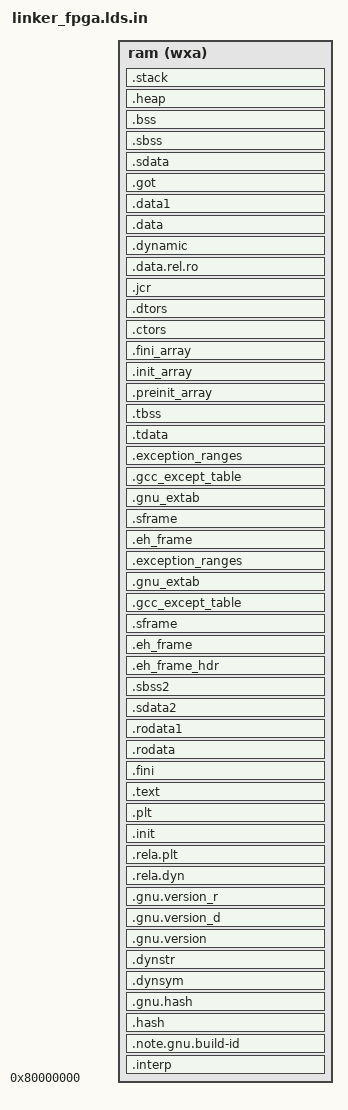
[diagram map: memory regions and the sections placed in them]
/* Patched script for RISC-V CPU */
/* Obtained using riscv32-unknown-elf-ld --verbose */

/* Copyright (C) 2014-2023 Free Software Foundation, Inc.
   Copying and distribution of this script, with or without modification,
   are permitted in any medium without royalty provided the copyright
   notice and this notice are preserved.  */

/*
Needs symbols from rvtarget.h
Memory sizes and origins
Heap and stack sizes
*/
#include <rvtarget.h>

OUTPUT_FORMAT("elf32-littleriscv", "elf32-littleriscv", "elf32-littleriscv")
OUTPUT_ARCH(riscv)
ENTRY(__rv_init) /* Setup boot as entry point */

/* Memory config of RISC-V CPU */
MEMORY
{
  ram (wxa)     : ORIGIN = 0x80000000,    LENGTH = FPGA_RAM_SIZE
}

SECTIONS
{
  /* Read-only sections, merged into text segment: */
  PROVIDE (__executable_start = SEGMENT_START("text-segment", 0x00000)); . = SEGMENT_START("text-segment", 0x00000);
  .interp         : { *(.interp) } > ram
  .note.gnu.build-id  : { *(.note.gnu.build-id) } > ram
  .hash           : { *(.hash) } > ram
  .gnu.hash       : { *(.gnu.hash) } > ram
  .dynsym         : { *(.dynsym) } > ram
  .dynstr         : { *(.dynstr) } > ram
  .gnu.version    : { *(.gnu.version) } > ram
  .gnu.version_d  : { *(.gnu.version_d) } > ram
  .gnu.version_r  : { *(.gnu.version_r) } > ram
  .rela.dyn       :
    {
      *(.rela.init)
      *(.rela.text .rela.text.* .rela.gnu.linkonce.t.*)
      *(.rela.fini)
      *(.rela.rodata .rela.rodata.* .rela.gnu.linkonce.r.*)
      *(.rela.data .rela.data.* .rela.gnu.linkonce.d.*)
      *(.rela.tdata .rela.tdata.* .rela.gnu.linkonce.td.*)
      *(.rela.tbss .rela.tbss.* .rela.gnu.linkonce.tb.*)
      *(.rela.ctors)
      *(.rela.dtors)
      *(.rela.got)
      *(.rela.sdata .rela.sdata.* .rela.gnu.linkonce.s.*)
      *(.rela.sbss .rela.sbss.* .rela.gnu.linkonce.sb.*)
      *(.rela.sdata2 .rela.sdata2.* .rela.gnu.linkonce.s2.*)
      *(.rela.sbss2 .rela.sbss2.* .rela.gnu.linkonce.sb2.*)
      *(.rela.bss .rela.bss.* .rela.gnu.linkonce.b.*)
      *(.rela.ifunc)
    } > ram
  .rela.plt       :
    {
      *(.rela.plt)
      PROVIDE_HIDDEN (__rela_iplt_start = .);
      *(.rela.iplt)
      PROVIDE_HIDDEN (__rela_iplt_end = .);
    } > ram
  .init           :
  {
    KEEP (*(SORT_NONE(.init)))
  } > ram
  .plt            : { *(.plt) *(.iplt) } > ram
  .text           :
  {
    *(.text.unlikely .text.*_unlikely .text.unlikely.*)
    *(.text.exit .text.exit.*)
    *(.text.startup .text.startup.*)
    *(.text.hot .text.hot.*)
    *(SORT(.text.sorted.*))
    *(.text .stub .text.* .gnu.linkonce.t.*)
    /* .gnu.warning sections are handled specially by elf.em.  */
    *(.gnu.warning)
  } > ram
  .fini           :
  {
    KEEP (*(SORT_NONE(.fini)))
  } > ram
  PROVIDE (__etext = .);
  PROVIDE (_etext = .);
  PROVIDE (etext = .);
  .rodata         : { *(.rodata .rodata.* .gnu.linkonce.r.*) } > ram
  .rodata1        : { *(.rodata1) } > ram
  .sdata2         :
  {
    *(.sdata2 .sdata2.* .gnu.linkonce.s2.*)
  } > ram
  .sbss2          : { *(.sbss2 .sbss2.* .gnu.linkonce.sb2.*) } > ram
  .eh_frame_hdr   : { *(.eh_frame_hdr) *(.eh_frame_entry .eh_frame_entry.*) } > ram
  .eh_frame       : ONLY_IF_RO { KEEP (*(.eh_frame)) *(.eh_frame.*) } > ram
  .sframe         : ONLY_IF_RO { *(.sframe) *(.sframe.*) } > ram
  .gcc_except_table   : ONLY_IF_RO { *(.gcc_except_table .gcc_except_table.*) } > ram
  .gnu_extab   : ONLY_IF_RO { *(.gnu_extab*) } > ram
  /* These sections are generated by the Sun/Oracle C++ compiler.  */
  .exception_ranges   : ONLY_IF_RO { *(.exception_ranges*) } > ram
  /* Adjust the address for the data segment.  We want to adjust up to
     the same address within the page on the next page up.  */
  . = DATA_SEGMENT_ALIGN (CONSTANT (MAXPAGESIZE), CONSTANT (COMMONPAGESIZE));
  /* Exception handling  */
  .eh_frame       : ONLY_IF_RW { KEEP (*(.eh_frame)) *(.eh_frame.*) } > ram
  .sframe         : ONLY_IF_RW { *(.sframe) *(.sframe.*) } > ram
  .gnu_extab      : ONLY_IF_RW { *(.gnu_extab) } > ram
  .gcc_except_table   : ONLY_IF_RW { *(.gcc_except_table .gcc_except_table.*) } > ram
  .exception_ranges   : ONLY_IF_RW { *(.exception_ranges*) } > ram
  /* Thread Local Storage sections  */
  .tdata	  :
   {
     PROVIDE_HIDDEN (__tdata_start = .);
     *(.tdata .tdata.* .gnu.linkonce.td.*)
   } > ram
  .tbss		  : { *(.tbss .tbss.* .gnu.linkonce.tb.*) *(.tcommon) } > ram
  .preinit_array    :
  {
    PROVIDE_HIDDEN (__preinit_array_start = .);
    KEEP (*(.preinit_array))
    PROVIDE_HIDDEN (__preinit_array_end = .);
  } > ram
  .init_array    :
  {
    PROVIDE_HIDDEN (__init_array_start = .);
    KEEP (*(SORT_BY_INIT_PRIORITY(.init_array.*) SORT_BY_INIT_PRIORITY(.ctors.*)))
    KEEP (*(.init_array EXCLUDE_FILE (*crtbegin.o *crtbegin?.o *crtend.o *crtend?.o ) .ctors))
    PROVIDE_HIDDEN (__init_array_end = .);
  } > ram
  .fini_array    :
  {
    PROVIDE_HIDDEN (__fini_array_start = .);
    KEEP (*(SORT_BY_INIT_PRIORITY(.fini_array.*) SORT_BY_INIT_PRIORITY(.dtors.*)))
    KEEP (*(.fini_array EXCLUDE_FILE (*crtbegin.o *crtbegin?.o *crtend.o *crtend?.o ) .dtors))
    PROVIDE_HIDDEN (__fini_array_end = .);
  } > ram
  .ctors          :
  {
    /* gcc uses crtbegin.o to find the start of
       the constructors, so we make sure it is
       first.  Because this is a wildcard, it
       doesn't matter if the user does not
       actually link against crtbegin.o; the
       linker won't look for a file to match a
       wildcard.  The wildcard also means that it
       doesn't matter which directory crtbegin.o
       is in.  */
    KEEP (*crtbegin.o(.ctors))
    KEEP (*crtbegin?.o(.ctors))
    /* We don't want to include the .ctor section from
       the crtend.o file until after the sorted ctors.
       The .ctor section from the crtend file contains the
       end of ctors marker and it must be last */
    KEEP (*(EXCLUDE_FILE (*crtend.o *crtend?.o ) .ctors))
    KEEP (*(SORT(.ctors.*)))
    KEEP (*(.ctors))
  } > ram
  .dtors          :
  {
    KEEP (*crtbegin.o(.dtors))
    KEEP (*crtbegin?.o(.dtors))
    KEEP (*(EXCLUDE_FILE (*crtend.o *crtend?.o ) .dtors))
    KEEP (*(SORT(.dtors.*)))
    KEEP (*(.dtors))
  } > ram
  .jcr            : { KEEP (*(.jcr)) } > ram
  .data.rel.ro : { *(.data.rel.ro.local* .gnu.linkonce.d.rel.ro.local.*) *(.data.rel.ro .data.rel.ro.* .gnu.linkonce.d.rel.ro.*) } > ram
  .dynamic        : { *(.dynamic) } > ram
  . = DATA_SEGMENT_RELRO_END (0, .);
  .data           :
  {
    __DATA_BEGIN__ = .;
    *(.data .data.* .gnu.linkonce.d.*)
    SORT(CONSTRUCTORS)
  } > ram
  .data1          : { *(.data1) } > ram
  .got            : { *(.got.plt) *(.igot.plt) *(.got) *(.igot) } > ram
  /* We want the small data sections together, so single-instruction offsets
     can access them all, and initialized data all before uninitialized, so
     we can shorten the on-disk segment size.  */
  .sdata          :
  {
    __SDATA_BEGIN__ = .;
    *(.srodata.cst16) *(.srodata.cst8) *(.srodata.cst4) *(.srodata.cst2) *(.srodata .srodata.*)
    *(.sdata .sdata.* .gnu.linkonce.s.*)
  } > ram
  _edata = .; PROVIDE (edata = .);
  . = .;
  __bss_start = .;
  .sbss           :
  {
    *(.dynsbss)
    *(.sbss .sbss.* .gnu.linkonce.sb.*)
    *(.scommon)
  } > ram
  .bss            :
  {
   *(.dynbss)
   *(.bss .bss.* .gnu.linkonce.b.*)
   *(COMMON)
   /* Align here to ensure that the .bss section occupies space up to
      _end.  Align after .bss to ensure correct alignment even if the
      .bss section disappears because there are no input sections.
      FIXME: Why do we need it? When there is no .bss section, we do not
      pad the .data section.  */
   . = ALIGN(. != 0 ? 32 / 8 : 1);
  } > ram
  . = ALIGN(32 / 8);
  . = SEGMENT_START("ldata-segment", .);
  . = ALIGN(32 / 8);
  __BSS_END__ = .;
    __global_pointer$ = MIN(__SDATA_BEGIN__ + 0x800, MAX(__DATA_BEGIN__ + 0x800, __BSS_END__ - 0x800));
  _end = .; PROVIDE (end = .);
  . = DATA_SEGMENT_END (.);

  .heap :
  {
    . = ALIGN(16);
    _heap_start = .;
    . += FPGA_HEAP_SIZE;
    _heap_end = .;
  } >ram
  
  .stack :
  {
    . = ALIGN(16);
    . += FPGA_STACK_SIZE;
    _stack_top = .;
  } >ram
}
